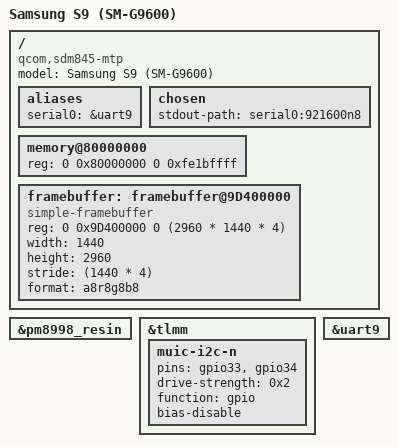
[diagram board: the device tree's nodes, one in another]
// SPDX-License-Identifier: GPL-2.0+
/*
 * Samsung S9 SM-G9600 (starqltechn) board device tree source
 *
 * (C) Copyright 2021 Dzmitry Sankouski <dsankouski@gmail.com>
 *
 */

/dts-v1/;

#include "sdm845.dtsi"
#include "pm8998.dtsi"

/ {
	model = "Samsung S9 (SM-G9600)";
	compatible = "qcom,sdm845-mtp", "qcom,sdm845", "qcom,mtp";

	aliases {
		serial0 = &uart9;
	};

	chosen {
		stdout-path = "serial0:921600n8";
	};

	memory@80000000 {
		device_type = "memory";
		reg = <0 0x80000000 0 0xfe1bffff>;
	};

	framebuffer: framebuffer@9D400000 {
		compatible = "simple-framebuffer";
		reg = <0 0x9D400000 0 (2960 * 1440 * 4)>;//2400000
		width = <1440>;
		height = <2960>;
		stride = <(1440 * 4)>;
		format = "a8r8g8b8";
	};
};

&pm8998_resin {
	status = "okay";
};

&tlmm {
	muic-i2c-n {
		pins = "gpio33", "gpio34";
		drive-strength = <0x2>;
		function = "gpio";
		bias-disable;
	};
};

&uart9 {
	status = "okay";
};
